# FM33FH0XX register map
File version: 1.0
CPU: SC000 r1p0, little endian, no MPU, no FPU, 3 interrupt priority bits
Registers are 32-bit, read-write, reset 0x0 unless marked. A register's access mark holds for its fields unless they carry their own. Offsets are from the block's base; [hi:lo] are bit positions; {n}, {i} and the like mark numbered series; 'fields as' and 'values as' point back to an identical list.

## FDCAN — FDCAN module information
Base 0x40020000
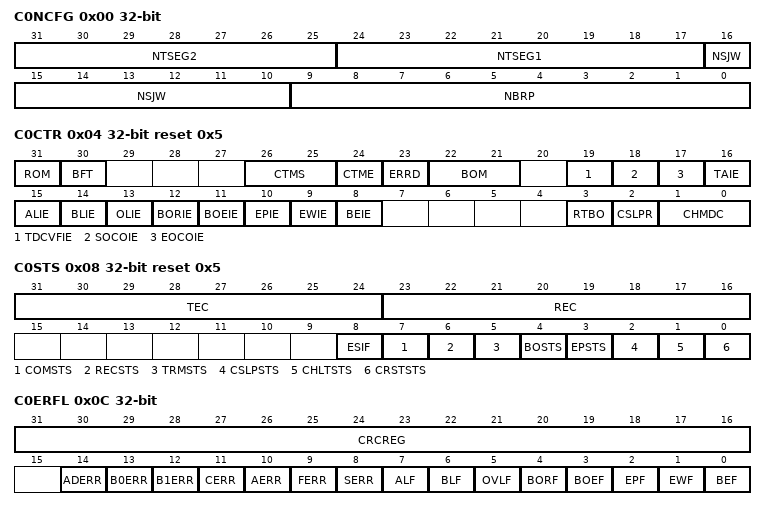
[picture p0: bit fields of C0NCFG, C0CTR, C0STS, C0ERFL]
0x00 C0NCFG
  [31:25] NTSEG2 — NTSEG2 field description
  [24:17] NTSEG1 — NTSEG1 field description
  [16:10] NSJW — NSJW field description
  [9:0] NBRP — NBRP field description
0x04 C0CTR reset 0x5
  [31] ROM — ROM field description
  [30] BFT — BFT field description
  [26:25] CTMS — CTMS field description
  [24] CTME — CTME field description
  [23] ERRD — ERRD field description
  [22:21] BOM — BOM field description
  [19] TDCVFIE — TDCVFIE field description
  [18] SOCOIE — SOCOIE field description
  [17] EOCOIE — EOCOIE field description
  [16] TAIE — TAIE field description
  [15] ALIE — ALIE field description
  [14] BLIE — BLIE field description
  [13] OLIE — OLIE field description
  [12] BORIE — BORIE field description
  [11] BOEIE — BOEIE field description
  [10] EPIE — EPIE field description
  [9] EWIE — EWIE field description
  [8] BEIE — BEIE field description
  [3] RTBO — RTBO field description
  [2] CSLPR — CSLPR field description
  [1:0] CHMDC — CHMDC field description
0x08 C0STS reset 0x5
  [31:24] TEC ro — TEC field description
  [23:16] REC ro — REC field description
  [8] ESIF — ESIF field description
  [7] COMSTS ro — COMSTS field description
  [6] RECSTS ro — RECSTS field description
  [5] TRMSTS ro — TRMSTS field description
  [4] BOSTS ro — BOSTS field description
  [3] EPSTS ro — EPSTS field description
  [2] CSLPSTS ro — CSLPSTS field description
  [1] CHLTSTS ro — CHLTSTS field description
  [0] CRSTSTS ro — CRSTSTS field description
0x0C C0ERFL
  [31:16] CRCREG — CRCREG field description
  [14] ADERR — ADERR field description
  [13] B0ERR — B0ERR field description
  [12] B1ERR — B1ERR field description
  [11] CERR — CERR field description
  [10] AERR — AERR field description
  [9] FERR — FERR field description
  [8] SERR — SERR field description
  [7] ALF — ALF field description
  [6] BLF — BLF field description
  [5] OVLF — OVLF field description
  [4] BORF — BORF field description
  [3] BOEF — BOEF field description
  [2] EPF — EPF field description
  [1] EWF — EWF field description
  [0] BEF — BEF field description
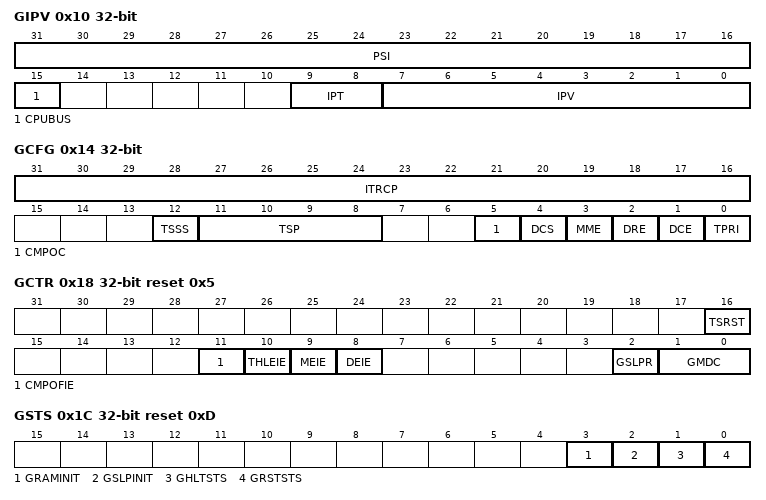
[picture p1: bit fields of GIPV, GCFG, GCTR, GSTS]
0x10 GIPV
  [31:16] PSI — PSI field description
  [15] CPUBUS — CPUBUS field description
  [9:8] IPT — IPT field description
  [7:0] IPV — IPV field description
0x14 GCFG
  [31:16] ITRCP — ITRCP field description
  [12] TSSS — TSSS field description
  [11:8] TSP — TSP field description
  [5] CMPOC — CMPOC field description
  [4] DCS — DCS field description
  [3] MME — MME field description
  [2] DRE — DRE field description
  [1] DCE — DCE field description
  [0] TPRI — TPRI field description
0x18 GCTR reset 0x5
  [16] TSRST — TSRST field description
  [11] CMPOFIE — CMPOFIE field description
  [10] THLEIE — THLEIE field description
  [9] MEIE — MEIE field description
  [8] DEIE — DEIE field description
  [2] GSLPR — GSLPR field description
  [1:0] GMDC — GMDC field description
0x1C GSTS reset 0xD
  [3] GRAMINIT ro — GRAMINIT field description
  [2] GSLPINIT ro — GSLPINIT field description
  [1] GHLTSTS ro — GHLTSTS field description
  [0] GRSTSTS ro — GRSTSTS field description
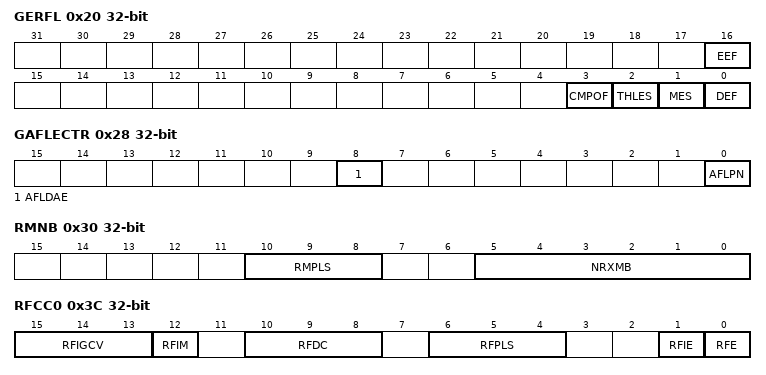
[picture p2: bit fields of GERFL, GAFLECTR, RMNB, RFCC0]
0x20 GERFL
  [16] EEF — EEF field description
  [3] CMPOF — CMPOF field description
  [2] THLES — THLES field description
  [1] MES — MES field description
  [0] DEF — DEF field description
0x24 GTSC
  [15:0] TS — TS field description
0x28 GAFLECTR
  [8] AFLDAE — AFLDAE field description
  [0] AFLPN — AFLPN field description
0x2C GAFLCFG
  [21:16] RNC — RNC field description
0x30 RMNB
  [10:8] RMPLS — RMPLS field description
  [5:0] NRXMB — NRXMB field description
0x34 RMND
  [31:0] RMNSU — RMNSU field description
0x38 RMIEC
  [31:0] RMIE — RMIE field description
0x3C RFCC0
  [15:13] RFIGCV — RFIGCV field description
  [12] RFIM — RFIM field description
  [10:8] RFDC — RFDC field description
  [6:4] RFPLS — RFPLS field description
  [1] RFIE — RFIE field description
  [0] RFE — RFE field description
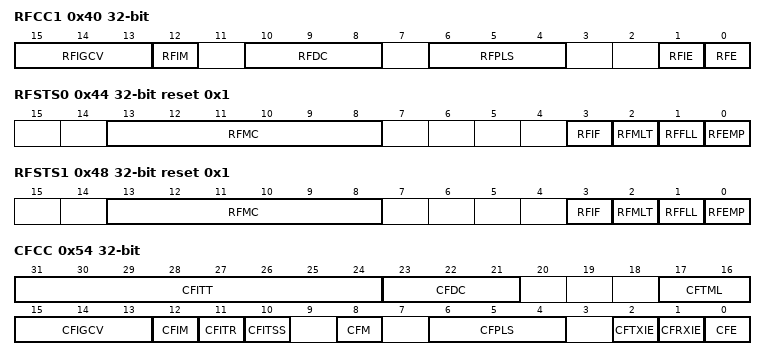
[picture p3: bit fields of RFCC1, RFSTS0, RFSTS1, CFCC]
0x40 RFCC1
  fields as RFCC0
0x44 RFSTS0 reset 0x1
  [13:8] RFMC ro — RFMC field description
  [3] RFIF — RFIF field description
  [2] RFMLT — RFMLT field description
  [1] RFFLL ro — RFFLL field description
  [0] RFEMP ro — RFEMP field description
0x48 RFSTS1 reset 0x1
  fields as RFSTS0
0x4C RFPCTR0
  [7:0] RFPC — RFPC field description
0x50 RFPCTR1
  [7:0] RFPC — RFPC field description
0x54 CFCC
  [31:24] CFITT — CFITT field description
  [23:21] CFDC — CFDC field description
  [17:16] CFTML — CFTML field description
  [15:13] CFIGCV — CFIGCV field description
  [12] CFIM — CFIM field description
  [11] CFITR — CFITR field description
  [10] CFITSS — CFITSS field description
  [8] CFM — CFM field description
  [6:4] CFPLS — CFPLS field description
  [2] CFTXIE — CFTXIE field description
  [1] CFRXIE — CFRXIE field description
  [0] CFE — CFE field description
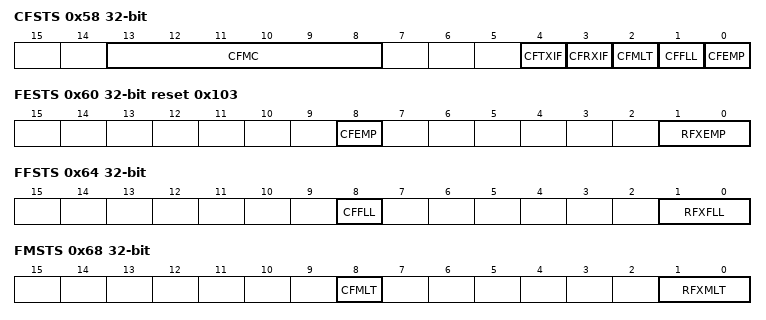
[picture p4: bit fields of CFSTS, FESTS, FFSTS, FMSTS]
0x58 CFSTS
  [13:8] CFMC — CFMC field description
  [4] CFTXIF — CFTXIF field description
  [3] CFRXIF — CFRXIF field description
  [2] CFMLT — CFMLT field description
  [1] CFFLL — CFFLL field description
  [0] CFEMP — CFEMP field description
0x5C CFPCTR
  [7:0] CFPC — CFPC field description
0x60 FESTS reset 0x103
  [8] CFEMP ro — CFEMP field description
  [1:0] RFXEMP ro — RFXEMP field description
0x64 FFSTS
  [8] CFFLL — CFFLL field description
  [1:0] RFXFLL — RFXFLL field description
0x68 FMSTS
  [8] CFMLT — CFMLT field description
  [1:0] RFXMLT — RFXMLT field description
0x6C RFISTS
  [1:0] RFXIF — RFXIF field description
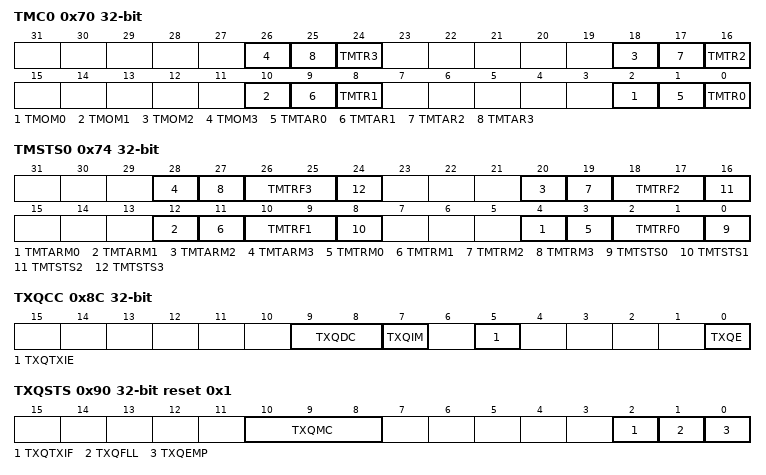
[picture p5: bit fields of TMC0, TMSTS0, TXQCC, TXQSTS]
0x70 TMC0
  [8n+2] TMOM{n} (n=0..3) — TMOM{n} field description
  [8n+1] TMTAR{n} (n=0..3) — TMTAR{n} field description
  [8n] TMTR{n} (n=0..3) — TMTR{n} field description
0x74 TMSTS0
  [8n+4] TMTARM{n} (n=0..3) — TMTARM{n} field description
  [8n+3] TMTRM{n} (n=0..3) — TMTRM{n} field description
  [8n+2:8n+1] TMTRF{n} (n=0..3) — TMTRF{n} field description
  [8n] TMTSTS{n} (n=0..3) — TMTSTS{n} field description
0x78 TMTRSTS
  [3:0] CFDTMTRSTS — CFDTMTRSTS field description
0x7C TMTARSTS
  [3:0] CFDTMTARSTS — CFDTMTARSTS field description
0x80 TMTCSTS
  [3:0] CFDTMTCSTS — CFDTMTCSTS field description
0x84 TMTASTS
  [3:0] CFDTMTASTS — CFDTMTASTS field description
0x88 TMIEC
  [3:0] TMIE — TMIE field description
0x8C TXQCC
  [9:8] TXQDC — TXQDC field description
  [7] TXQIM — TXQIM field description
  [5] TXQTXIE — TXQTXIE field description
  [0] TXQE — TXQE field description
0x90 TXQSTS reset 0x1
  [10:8] TXQMC — TXQMC field description
  [2] TXQTXIF — TXQTXIF field description
  [1] TXQFLL — TXQFLL field description
  [0] TXQEMP — TXQEMP field description
0x94 TXQPCTR
  [7:0] TXQPC — TXQPC field description
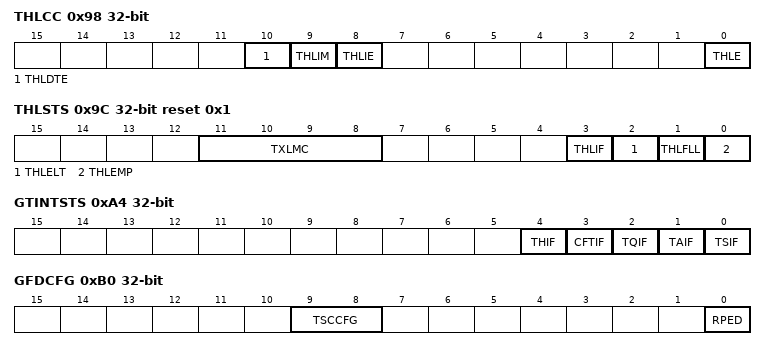
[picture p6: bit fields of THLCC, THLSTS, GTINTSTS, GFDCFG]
0x98 THLCC
  [10] THLDTE — THLDTE field description
  [9] THLIM — THLIM field description
  [8] THLIE — THLIE field description
  [0] THLE — THLE field description
0x9C THLSTS reset 0x1
  [11:8] TXLMC — TXLMC field description
  [3] THLIF — THLIF field description
  [2] THLELT — THLELT field description
  [1] THLFLL — THLFLL field description
  [0] THLEMP — THLEMP field description
0xA0 THLPCTR
  [7:0] THLPC — THLPC field description
0xA4 GTINTSTS
  [4] THIF — THIF field description
  [3] CFTIF — CFTIF field description
  [2] TQIF — TQIF field description
  [1] TAIF — TAIF field description
  [0] TSIF — TSIF field description
0xA8 GTSTCFG
  [19:16] RTMPS — RTMPS field description
0xAC GTSTCTR
  [2] RTME — RTME field description
0xB0 GFDCFG
  [9:8] TSCCFG — TSCCFG field description
  [0] RPED — RPED field description
0xB8 GLOCKK
  [15:0] LOCK — LOCK field description
0xC0 GAFLIGNENT
  [4:0] IRN — IRN field description
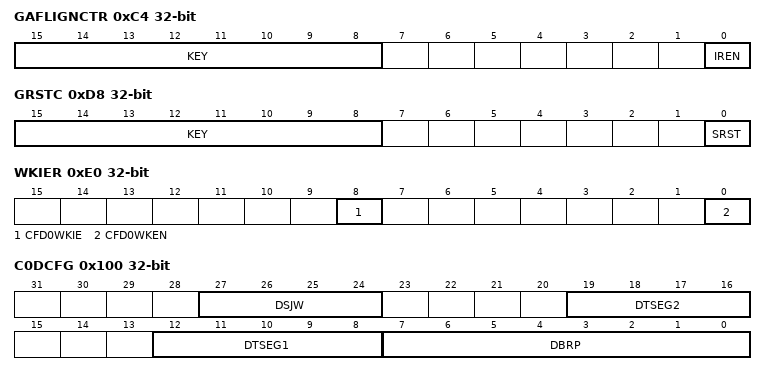
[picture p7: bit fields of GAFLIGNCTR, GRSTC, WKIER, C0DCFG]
0xC4 GAFLIGNCTR
  [15:8] KEY — KEY field description
  [0] IREN — IREN field description
0xD0 GPFLECTR
  [8] PFLDAE — PFLDAE field description
0xD4 GPFLCFG
  [25:24] RNC — RNC field description
0xD8 GRSTC
  [15:8] KEY — KEY field description
  [0] SRST — SRST field description
0xE0 WKIER
  [8] CFD0WKIE — CFD0WKIE field description
  [0] CFD0WKEN — CFD0WKEN field description
0xE4 WKISR
  [0] CFD0WKIF — CFD0WKIF field description
0x100 C0DCFG
  [27:24] DSJW — DSJW field description
  [19:16] DTSEG2 — DTSEG2 field description
  [12:8] DTSEG1 — DTSEG1 field description
  [7:0] DBRP — DBRP field description
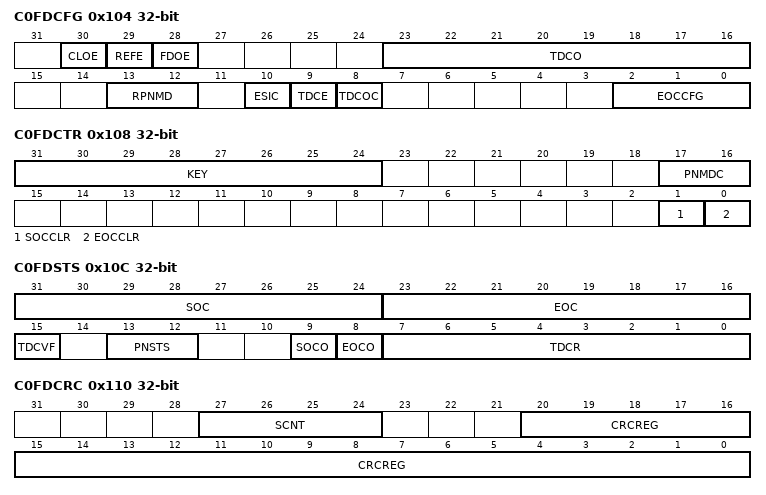
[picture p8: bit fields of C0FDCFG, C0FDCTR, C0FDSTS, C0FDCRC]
0x104 C0FDCFG
  [30] CLOE — CLOE field description
  [29] REFE — REFE field description
  [28] FDOE — FDOE field description
  [23:16] TDCO — TDCO field description
  [13:12] RPNMD — RPNMD field description
  [10] ESIC — ESIC field description
  [9] TDCE — TDCE field description
  [8] TDCOC — TDCOC field description
  [2:0] EOCCFG — EOCCFG field description
0x108 C0FDCTR
  [31:24] KEY — KEY field description
  [17:16] PNMDC — PNMDC field description
  [1] SOCCLR — SOCCLR field description
  [0] EOCCLR — EOCCLR field description
0x10C C0FDSTS
  [31:24] SOC — SOC field description
  [23:16] EOC — EOC field description
  [15] TDCVF — TDCVF field description
  [13:12] PNSTS — PNSTS field description
  [9] SOCO — SOCO field description
  [8] EOCO — EOCO field description
  [7:0] TDCR — TDCR field description
0x110 C0FDCRC
  [27:24] SCNT — SCNT field description
  [20:0] CRCREG — CRCREG field description
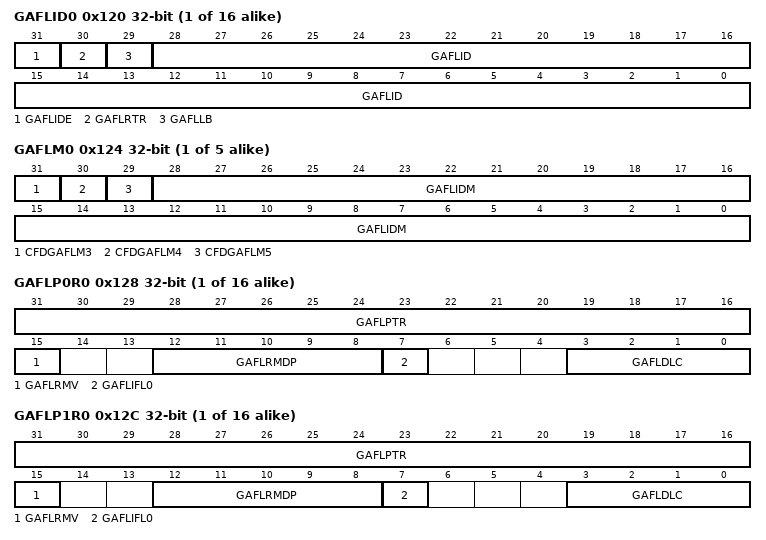
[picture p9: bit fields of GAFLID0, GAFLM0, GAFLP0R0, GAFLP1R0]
{0x120+0x10*i} GAFLID{i} (i=0..15)
  [31] GAFLIDE — GAFLIDE field description
  [30] GAFLRTR — GAFLRTR field description
  [29] GAFLLB — GAFLLB field description
  [28:0] GAFLID — GAFLID field description
{0x124+0x10*i} GAFLM{i} (i=0..4)
  [31] CFDGAFLM3 — CFDGAFLM3 field description
  [30] CFDGAFLM4 — CFDGAFLM4 field description
  [29] CFDGAFLM5 — CFDGAFLM5 field description
  [28:0] GAFLIDM — GAFLIDM field description
{0x128+0x10*i} GAFLP0R{i} (i=0..15)
  [31:16] GAFLPTR — GAFLPTR field description
  [15] GAFLRMV — GAFLRMV field description
  [12:8] GAFLRMDP — GAFLRMDP field description
  [7] GAFLIFL0 — GAFLIFL0 field description
  [3:0] GAFLDLC — GAFLDLC field description
{0x12C+0x10*i} GAFLP1R{i} (i=0..15)
  fields as GAFLP0R0
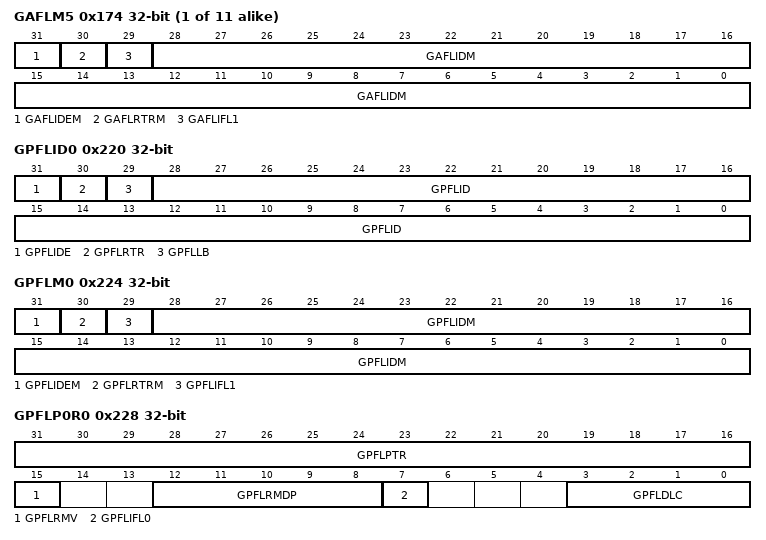
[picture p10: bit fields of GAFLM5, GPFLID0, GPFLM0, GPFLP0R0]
{0x124+0x10*i} GAFLM{i} (i=5..15)
  [31] GAFLIDEM — GAFLIDEM field description
  [30] GAFLRTRM — GAFLRTRM field description
  [29] GAFLIFL1 — GAFLIFL1 field description
  [28:0] GAFLIDM — GAFLIDM field description
0x220 GPFLID0
  [31] GPFLIDE — GPFLIDE field description
  [30] GPFLRTR — GPFLRTR field description
  [29] GPFLLB — GPFLLB field description
  [28:0] GPFLID — GPFLID field description
0x224 GPFLM0
  [31] GPFLIDEM — GPFLIDEM field description
  [30] GPFLRTRM — GPFLRTRM field description
  [29] GPFLIFL1 — GPFLIFL1 field description
  [28:0] GPFLIDM — GPFLIDM field description
0x228 GPFLP0R0
  [31:16] GPFLPTR — GPFLPTR field description
  [15] GPFLRMV — GPFLRMV field description
  [12:8] GPFLRMDP — GPFLRMDP field description
  [7] GPFLIFL0 — GPFLIFL0 field description
  [3:0] GPFLDLC — GPFLDLC field description
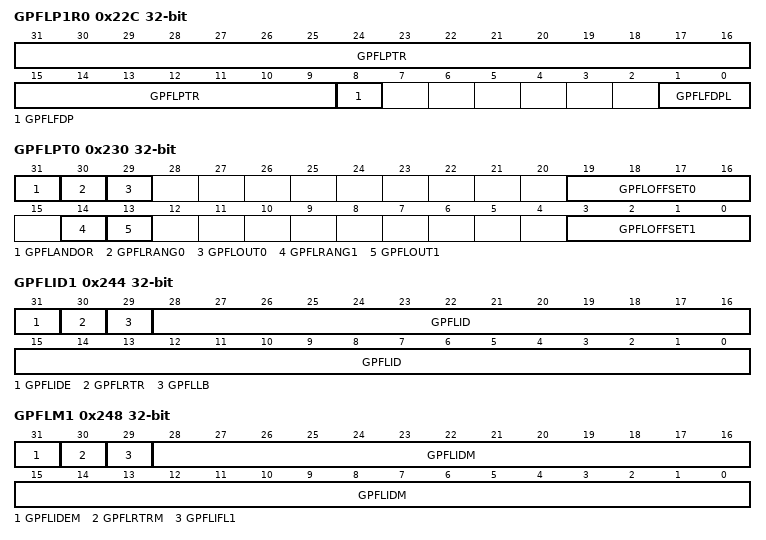
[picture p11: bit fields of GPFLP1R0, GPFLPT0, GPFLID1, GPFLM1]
0x22C GPFLP1R0
  [31:9] GPFLPTR — GPFLPTR field description
  [8] GPFLFDP — GPFLFDP field description
  [1:0] GPFLFDPL — GPFLFDPL field description
0x230 GPFLPT0
  [31] GPFLANDOR — GPFLANDOR field description
  [30] GPFLRANG0 — GPFLRANG0 field description
  [29] GPFLOUT0 — GPFLOUT0 field description
  [19:16] GPFLOFFSET0 — GPFLOFFSET0 field description
  [14] GPFLRANG1 — GPFLRANG1 field description
  [13] GPFLOUT1 — GPFLOUT1 field description
  [3:0] GPFLOFFSET1 — GPFLOFFSET1 field description
0x234 GPFLPD0R0
  [31:0] FDATA — FDATA field description
0x238 CANFD_GPFLPM0R0
  [31:0] FMASK — FMASK field description
0x23C GPFLPD1R0
  [31:0] FDATA — FDATA field description
0x240 GPFLPM1R0
  [31:0] FMASK — FMASK field description
0x244 GPFLID1
  fields as GPFLID0
0x248 GPFLM1
  fields as GPFLM0
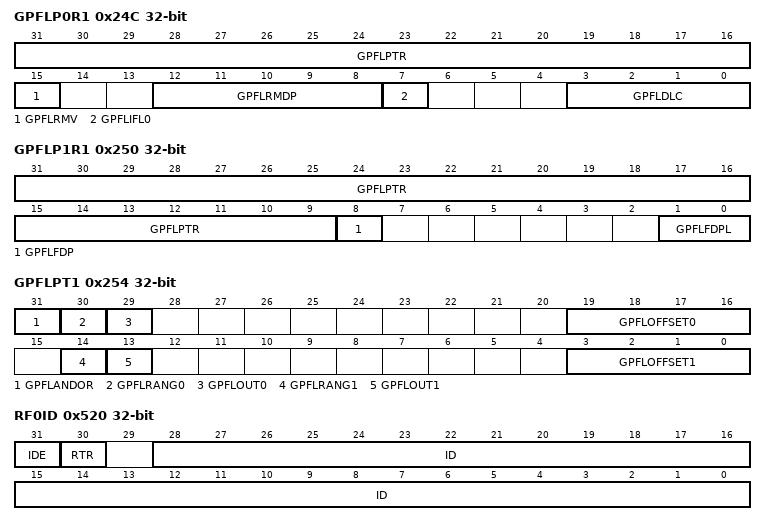
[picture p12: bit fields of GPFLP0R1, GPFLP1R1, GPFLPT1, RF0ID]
0x24C GPFLP0R1
  fields as GPFLP0R0
0x250 GPFLP1R1
  fields as GPFLP1R0
0x254 GPFLPT1
  fields as GPFLPT0
0x258 GPFLPD0R1
  [31:0] FDATA — FDATA field description
0x25C GPFLPM0R1
  [31:0] FMASK — FMASK field description
0x260 GPFLPD1R1
  [31:0] FDATA — FDATA field description
0x264 GPFLPM1R1
  [31:0] FMASK — FMASK field description
{0x280+4i} RPGACC{i} (i=0..63)
  [31:0] RDTA — RDTA field description
0x520 RF0ID
  [31] IDE ro — IDE field description
  [30] RTR ro — RTR field description
  [28:0] ID ro — ID field description
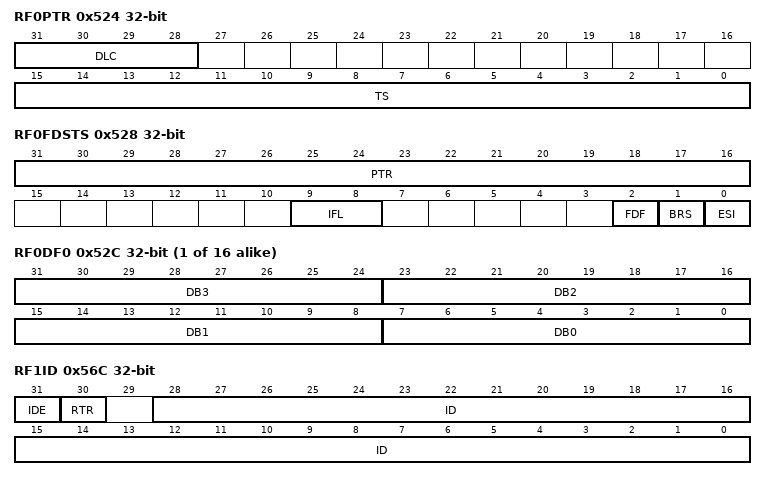
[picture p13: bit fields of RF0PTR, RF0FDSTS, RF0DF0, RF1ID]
0x524 RF0PTR
  [31:28] DLC ro — DLC field description
  [15:0] TS ro — TS field description
0x528 RF0FDSTS
  [31:16] PTR ro — PTR field description
  [9:8] IFL ro — IFL field description
  [2] FDF ro — FDF field description
  [1] BRS ro — BRS field description
  [0] ESI ro — ESI field description
{0x52C+4i} RF0DF{i} (i=0..15)
  [8n+7:8n] DB{n} ro (n=0..3) — DB{n} field description
0x56C RF1ID
  fields as RF0ID
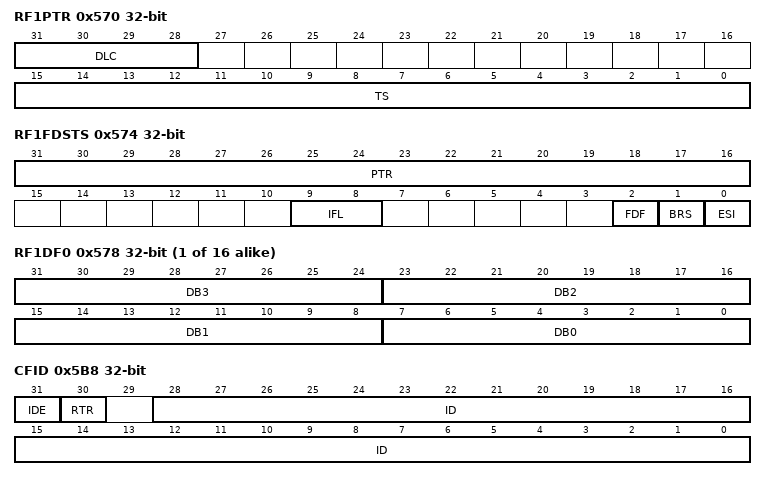
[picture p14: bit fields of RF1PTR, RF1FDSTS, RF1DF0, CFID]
0x570 RF1PTR
  fields as RF0PTR
0x574 RF1FDSTS
  fields as RF0FDSTS
{0x578+4i} RF1DF{i} (i=0..15)
  [8n+7:8n] DB{n} ro (n=0..3) — DB{n} field description
0x5B8 CFID
  fields as RF0ID
0x5BC CFPTR
  fields as RF0PTR
0x5C0 CFFDSTS
  fields as RF0FDSTS
{0x5C4+4i} CFDF{i} (i=0..15)
  [8n+7:8n] DB{n} ro (n=0..3) — DB{n} field description
{0x604+0x4C*i} TM{i}ID (i=0..3)
  fields as RF0ID
{0x608+0x4C*i} TM{i}PTR (i=0..3)
  fields as RF0PTR
{0x60C+0x4C*i} TM{i}FDSTS (i=0..3)
  fields as RF0FDSTS
{0x610+4i} TM0DF{i} (i=0..15)
  [8n+7:8n] DB{n} ro (n=0..3) — DB{n} field description
{0x65C+4i} TM1DF{i} (i=0..15)
  [8n+7:8n] DB{n} ro (n=0..3) — DB{n} field description
{0x6A8+4i} TM2DF{i} (i=0..15)
  [8n+7:8n] DB{n} ro (n=0..3) — DB{n} field description
{0x6F4+4i} TM3DF{i} (i=0..15)
  [8n+7:8n] DB{n} ro (n=0..3) — DB{n} field description
0x740 THLACC0
  [31:16] TMTS — TMTS field description
  [4:3] BN — BN field description
  [2:0] BT — BT field description
0x744 THLACC1
  [17:16] TIFL — TIFL field description
  [15:0] TID — TID field description
